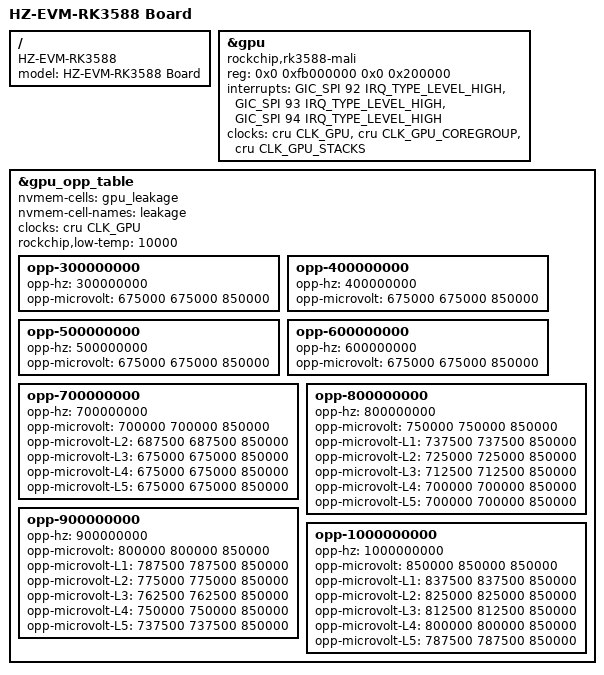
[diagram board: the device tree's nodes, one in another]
/dts-v1/;

#include "HZ-EVM-RK3588.dtsi"
//#include "HZ-EVM-RK3588_MIPI_DSI.dtsi"

/ {
    model = "HZ-EVM-RK3588 Board";
	compatible = "HZ-EVM-RK3588", "rockchip,rk3588-evb7-lp4-v10", "rockchip,rk3588";
};

&gpu {
    compatible = "rockchip,rk3588-mali", "arm,mali-valhall-csf";
    reg = <0x0 0xfb000000 0x0 0x200000>;
    interrupts = <GIC_SPI 92 IRQ_TYPE_LEVEL_HIGH>,
                <GIC_SPI 93 IRQ_TYPE_LEVEL_HIGH>,
                <GIC_SPI 94 IRQ_TYPE_LEVEL_HIGH>;
    interrupt-names = "job", "mmu", "gpu";

    clock-names = "core", "coregroup", "stacks";
    clocks = <&cru CLK_GPU>, <&cru CLK_GPU_COREGROUP>,
            <&cru CLK_GPU_STACKS>;

    // /delete-property/ upthreshold;
    // /delete-property/ downdifferential;
};

&gpu_opp_table {
    nvmem-cells = <&gpu_leakage>;
    nvmem-cell-names = "leakage";

    /delete-property/ rockchip,supported-hw;
    /delete-property/ rockchip,pvtm-hw;
    /delete-property/ rockchip,pvtm-voltage-sel-hw;
    
    /delete-property/ rockchip,opp-clocks;

    clocks = <&cru CLK_GPU>;
    clock-names = "clk";
    rockchip,low-temp = <10000>;

    opp-300000000 {
        /delete-property/ opp-supported-hw;
        opp-hz = /bits/ 64 <300000000>;
        opp-microvolt = <675000 675000 850000>;
    };
    opp-400000000 {
        /delete-property/ opp-supported-hw;
        opp-hz = /bits/ 64 <400000000>;
        opp-microvolt = <675000 675000 850000>;
    };
    opp-500000000 {
        /delete-property/ opp-supported-hw;
        opp-hz = /bits/ 64 <500000000>;
        opp-microvolt = <675000 675000 850000>;
    };
    opp-600000000 {
        /delete-property/ opp-supported-hw;
        opp-hz = /bits/ 64 <600000000>;
        opp-microvolt = <675000 675000 850000>;
    };
    opp-700000000 {
        /delete-property/ opp-supported-hw;
        opp-hz = /bits/ 64 <700000000>;
        opp-microvolt = <700000 700000 850000>;
        opp-microvolt-L2 = <687500 687500 850000>;
        opp-microvolt-L3 = <675000 675000 850000>;
        opp-microvolt-L4 = <675000 675000 850000>;
        opp-microvolt-L5 = <675000 675000 850000>;
    };
    opp-800000000 {
        /delete-property/ opp-supported-hw;
        opp-hz = /bits/ 64 <800000000>;
        opp-microvolt = <750000 750000 850000>;
        opp-microvolt-L1 = <737500 737500 850000>;
        opp-microvolt-L2 = <725000 725000 850000>;
        opp-microvolt-L3 = <712500 712500 850000>;                                     
        opp-microvolt-L4 = <700000 700000 850000>;
        opp-microvolt-L5 = <700000 700000 850000>;
    };
    opp-900000000 {
        /delete-property/ opp-supported-hw;
        opp-hz = /bits/ 64 <900000000>;
        opp-microvolt = <800000 800000 850000>;
        opp-microvolt-L1 = <787500 787500 850000>;
        opp-microvolt-L2 = <775000 775000 850000>;
        opp-microvolt-L3 = <762500 762500 850000>;
        opp-microvolt-L4 = <750000 750000 850000>;
        opp-microvolt-L5 = <737500 737500 850000>;
    };
    opp-1000000000 {
        /delete-property/ opp-supported-hw;
        opp-hz = /bits/ 64 <1000000000>;
        opp-microvolt = <850000 850000 850000>;
        opp-microvolt-L1 = <837500 837500 850000>;
        opp-microvolt-L2 = <825000 825000 850000>;
        opp-microvolt-L3 = <812500 812500 850000>;
        opp-microvolt-L4 = <800000 800000 850000>;
        opp-microvolt-L5 = <787500 787500 850000>;
    };

    /delete-node/ opp-j-m-300000000;
    /delete-node/ opp-j-m-400000000;
	/delete-node/ opp-j-m-500000000;
	/delete-node/ opp-j-m-600000000;
	/delete-node/ opp-j-m-700000000;
	/delete-node/ opp-j-850000000;
	/delete-node/ opp-m-800000000;
	/delete-node/ opp-m-900000000;
	/delete-node/ opp-m-1000000000;
};
